# AM335x register map
Vendor: Texas Instruments; Series: Sitara AM335x; File version: 1.1
CPU: Cortex-A8 r0p0, little endian
Registers are 32-bit, read-write, reset 0x0 unless marked. A register's access mark holds for its fields unless they carry their own. Offsets are from the block's base; [hi:lo] are bit positions; 'fields as' and 'values as' point back to an identical list.

## GPIO0 — GPIO0 module
Base 0x44E07000
Same registers: GPIO1 0x4804C000, GPIO2 0x481AC000, GPIO3 0x481AE000
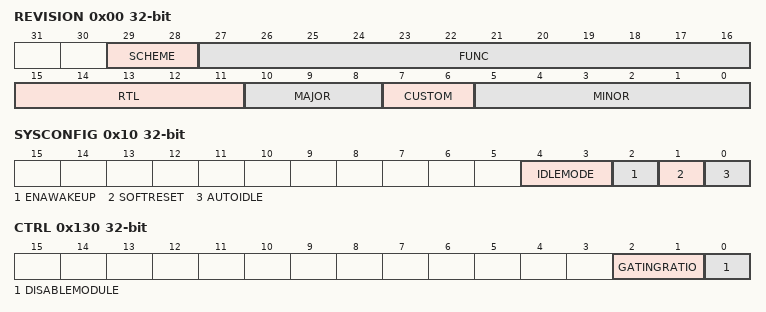
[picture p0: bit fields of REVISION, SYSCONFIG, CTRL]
0x00 REVISION — GPIO_REVISION Register
  [29:28] SCHEME — bit: 30,31 (R) Used to distinguish between old Scheme and current.
  [27:16] FUNC ro — Indicates a software compatible module family.
  [15:11] RTL ro — RTL version
  [10:8] MAJOR ro — Major Revision
  [7:6] CUSTOM — bit: 6,7 (R) Indicates a special version for a particular device.
  [5:0] MINOR ro — Minor Revision
0x10 SYSCONFIG — GPIO_SYSCONFIG Register
  [4:3] IDLEMODE — bit: 3,4 (RW) Power Management, Req/Ack control. [see e_GPIO_IDLEMODE]
  [2] ENAWAKEUP — bit: 2 (RW) Enable wakeup
  [1] SOFTRESET — bit: 1 (RW) Software reset. This bit is automatically reset by the hardware. During reads, it always returns 0
  [0] AUTOIDLE — bit: 0 (RW) Internal interface clock gating strategy
0x20 EOI — GPIO_EOI Register
  [0] DMAEvent_Ack — bit: 0 (RW) Write 0 to acknowledge DMA event has been completed.
0x24 IRQSTATUS_RAW_0 — GPIO_IRQSTATUS_RAW_0 Register
  [31:0] INTLINE — Interrupt n status. [0x0 = No effect, 0x1 = IRQ is triggered]
0x28 IRQSTATUS_RAW_1 — GPIO_IRQSTATUS_RAW_1 Register
  fields as IRQSTATUS_RAW_0
0x2C IRQSTATUS_0 — GPIO_IRQSTATUS_0 Register
  [31:0] INTLINE — (RW1C) Interrupt n status.
0x30 IRQSTATUS_1 — GPIO_IRQSTATUS_1 Register
  [31:0] INTLINE — (RW1C) Interrupt n status.
0x34 IRQSTATUS_SET_0 — GPIO_IRQSTATUS_SET_0 Register
  [31:0] INTLINE — Interrupt n enable. [0x0 = No effect, 0x1 = Enable IRQ generation]
0x38 IRQSTATUS_SET_1 — GPIO_IRQSTATUS_SET_1 Register
  fields as IRQSTATUS_SET_0
0x3C IRQSTATUS_CLR_0 — GPIO_IRQSTATUS_CLR_0 Register
  [31:0] INTLINE — Interrupt n enable. [0x0 = No effect, 0x1 = Disable IRQ generation]
0x40 IRQSTATUS_CLR_1 — GPIO_IRQSTATUS_CLR_1 Register
  fields as IRQSTATUS_CLR_0
0x44 IRQWAKEN_0 — GPIO_IRQWAKEN_0 Register
  fields as IRQSTATUS_CLR_0
0x48 IRQWAKEN_1 — GPIO_IRQWAKEN_1 Register
  fields as IRQSTATUS_CLR_0
0x114 SYSSTATUS — GPIO_SYSSTATUS Register
  [0] RESETDONE — bit: 0 (R) Reset status information. [0x0 = Internal Reset is on-going, 0x1 = Reset completed]
0x130 CTRL — GPIO_CTRL Register
  [2:1] GATINGRATIO — Gating Ratio. Controls the clock gating for the event detection logic. [see e_GPIO_GATINGRATIO]
  [0] DISABLEMODULE — bit: 0 (RW) Module Disable [0x0 = Module is enabled, clk are not gated, 0x1 = Module is disabled, clk are gated]
0x134 OE — GPIO_OE Register
  [31:0] OUTPUTEN — Output Data Enable [0x0 = The corresponding GPIO port is configured as an output, 0x1 = configured as an input]
0x138 DATAIN — GPIO_DATAIN Register
  [31:0] DATAIN ro — Sampled Input Data
0x13C DATAOUT — GPIO_DATAOUT Register
  [31:0] DATAOUT — Data to set on output pins
0x140 LEVELDETECT0 — GPIO_LEVELDETECT0 Register
  [31:0] LEVELDETECT0 — Low Level Interrupt Enable [0x0 = Disable the IRQ assertion on low-level detect, 0x1 = Enable]
0x144 LEVELDETECT1 — GPIO_LEVELDETECT1 Register
  [31:0] LEVELDETECT1 — High Level Interrupt Enable [0x0 = Disable the IRQ assertion on high-level detect, 0x1 = Enable]
0x148 RISINGDETECT — GPIO_RISINGDETECT Register
  [31:0] RISINGDETECT — Rising Edge Interrupt Enable [0x0 = Disable IRQ on rising-edge detect, 0x1 = Enable]
0x14C FALLINGDETECT — GPIO_FALLINGDETECT Register
  [31:0] FALLINGDETECT — Falling Edge Interrupt Enable [0x0 = Disable IRQ on falling-edge detect, 0x1 = Enable]
0x150 DEBOUNCENABLE — GPIO_DEBOUNCENABLE Register
  [31:0] DEBOUNCEENABLE — Input Debounce Enable [0x0 = Disable debouncing feature on the corresponding input port, 0x1 = Enable]
0x154 DEBOUNCINGTIME — GPIO_DEBOUNCINGTIME Register
  [7:0] DEBOUNCETIME — Input Debouncing Value in 31 microsecond steps. Debouncing Value = (DEBOUNCETIME + 1) * 31 microseconds
0x190 CLEARDATAOUT — GPIO_CLEARDATAOUT Register
  [31:0] INTLINE — Clear Data Output Register [0x0 = No effect, 0x1 = Clear the corresponding bit in the GPIO_DATAOUT register]
0x194 SETDATAOUT — GPIO_SETDATAOUT Register
  [31:0] INTLINE — Set Data Output Register [0x0 = No effect, 0x1 = Set the corresponding bit in the GPIO_DATAOUT register]
